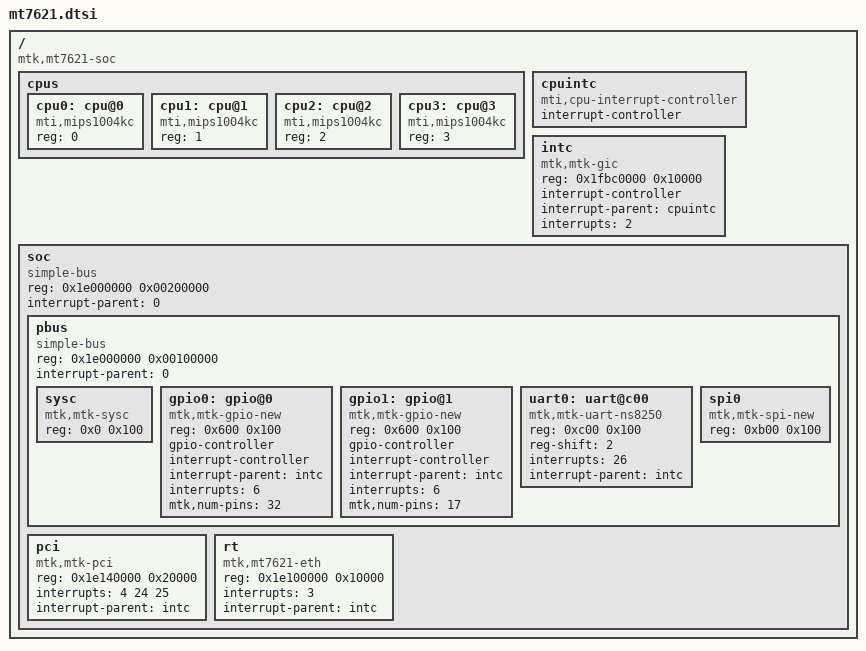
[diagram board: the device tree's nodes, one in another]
/*
 * Copyright (c) 2016, Stanislav Galabov
 */

/ {
	#address-cells = <1>;
	#size-cells = <1>;
	compatible = "mtk,mt7621-soc";

	cpus {
		#address-cells = <1>;
		#size-cells = <0>;

		cpu0: cpu@0 {
			compatible = "mti,mips1004kc";
			reg = <0>;
		};

		cpu1: cpu@1 {
			compatible = "mti,mips1004kc";
			reg = <1>;
		};

		cpu2: cpu@2 {
			compatible = "mti,mips1004kc";
			reg = <2>;
		};

		cpu3: cpu@3 {
			compatible = "mti,mips1004kc";
			reg = <3>;
		};
	};

	cpuintc: cpuintc {
		#address-cells = <0>;
		#interrupt-cells = <1>;
		interrupt-controller;
		compatible = "mti,cpu-interrupt-controller";
	};

	intc: intc {
		compatible = "mtk,mtk-gic";
		reg = <0x1fbc0000 0x10000>;

		interrupt-controller;
		#interrupt-cells = <1>;

		interrupt-parent = <&cpuintc>;
		interrupts = <2>;

		status = "okay";
	};

	soc {
		device_type = "soc";
		compatible = "simple-bus";
		reg = <0x1e000000 0x00200000>;
		ranges = <0x0 0x0 0x1FFFFFFF>;
		#address-cells = <1>;
		#size-cells = <1>;
		interrupt-parent = <0>;

		pbus {
		    compatible = "simple-bus";
		    reg = <0x1e000000 0x00100000>;
		    ranges = <0x0 0x1e000000 0x1FFFFF>;
		    #address-cells = <1>;
		    #size-cells = <1>;
		    interrupt-parent = <0>;

		    sysc: sysc {
			compatible="mtk,mtk-sysc", "ralink,rt305x-sysc";
			reg = <0x0 0x100>;
		    };

		    gpio0: gpio@0 {
                        compatible = "mtk,mtk-gpio-new";
                        reg = <0x600 0x100>;

                        gpio-controller;
                        #gpio-cells = <2>;

                        interrupt-controller;
                        #interrupt-cells = <2>;

                        interrupt-parent = <&intc>;
                        interrupts = <6>;

                        mtk,num-pins = <32>;

                        status = "okay";
                    };

                    gpio1: gpio@1 {
                        compatible = "mtk,mtk-gpio-new";
                        reg = <0x600 0x100>;

                        gpio-controller;
                        #gpio-cells = <2>;

                        interrupt-controller;
                        #interrupt-cells = <2>;

                        interrupt-parent = <&intc>;
                        interrupts = <6>;

                        mtk,num-pins = <17>;

                        status = "okay";
                    };

		    uart0: uart@c00 {
			device_type = "serial";
			compatible = "mtk,mtk-uart-ns8250";
			reg = <0xc00 0x100>;
/*			clock-frequency = <50000000>;
			current-speed = <115200>;*/
			reg-shift = <2>;
			interrupts = <26>;
			interrupt-parent = <&intc>;
		    };

		    spi0 {
                        compatible = "mtk,mtk-spi-new";
                        reg = < 0xb00 0x100 >;
                        status = "okay";
                    };

		};

		pci {
                    compatible = "mtk,mtk-pci";
                    reg = <0x1e140000 0x20000>;
		    ranges = <1 0x1e160000 0x00010000
			      2 0x60000000 0x10000000>;
                    interrupts = <4 24 25>;
                    interrupt-parent = <&intc>;
                    status = "okay";
                };


		rt {
                	compatible = "mtk,mt7621-eth";
                        reg = <0x1e100000 0x10000>;
                        status = "okay";
                        interrupts = <3>;
                        interrupt-parent = <&intc>;
                };
	};
};

